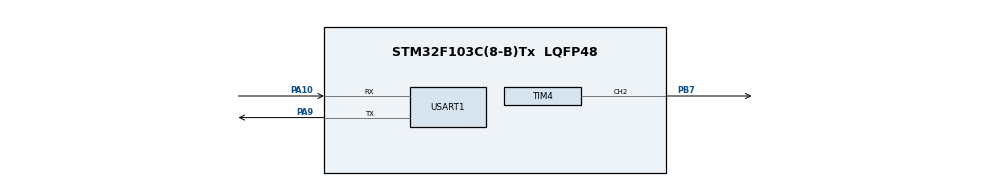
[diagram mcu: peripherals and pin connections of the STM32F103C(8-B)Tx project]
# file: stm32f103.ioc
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Dma.Request0=TIM4_CH2
Dma.Request1=USART1_RX
Dma.TIM4_CH2.0.Direction=DMA_MEMORY_TO_PERIPH
Dma.TIM4_CH2.0.Instance=DMA1_Channel4
Dma.TIM4_CH2.0.MemDataAlignment=DMA_MDATAALIGN_BYTE
Dma.TIM4_CH2.0.MemInc=DMA_MINC_ENABLE
Dma.TIM4_CH2.0.Mode=DMA_NORMAL
Dma.TIM4_CH2.0.PeriphDataAlignment=DMA_PDATAALIGN_HALFWORD
Dma.TIM4_CH2.0.PeriphInc=DMA_PINC_DISABLE
Dma.TIM4_CH2.0.Priority=DMA_PRIORITY_HIGH
Dma.USART1_RX.1.Direction=DMA_PERIPH_TO_MEMORY
Dma.USART1_RX.1.Instance=DMA1_Channel5
Dma.USART1_RX.1.MemDataAlignment=DMA_MDATAALIGN_BYTE
Dma.USART1_RX.1.MemInc=DMA_MINC_ENABLE
Dma.USART1_RX.1.Mode=DMA_NORMAL
Dma.USART1_RX.1.PeriphDataAlignment=DMA_PDATAALIGN_BYTE
Dma.USART1_RX.1.PeriphInc=DMA_PINC_DISABLE
Dma.USART1_RX.1.Priority=DMA_PRIORITY_HIGH
FREERTOS.BinarySemaphores01=ledCtrlSem,Dynamic,NULL
FREERTOS.Tasks01=LedSchedule,0,128,startLedSchedule,Default,NULL,Dynamic,NULL,NULL
Mcu.Family=STM32F1
Mcu.Name=STM32F103C(8-B)Tx
Mcu.Package=LQFP48
NVIC.DMA1_Channel4_IRQn=true\:5\:0\:false\:false\:true\:true\:false
NVIC.DMA1_Channel5_IRQn=true\:5\:0\:false\:false\:true\:true\:false
NVIC.PriorityGroup=NVIC_PRIORITYGROUP_4
NVIC.USART1_IRQn=true\:5\:0\:false\:false\:true\:true\:true
PA10.Mode=Asynchronous
PA10.Signal=USART1_RX
PA13.Mode=Serial_Wire
PA13.Signal=SYS_JTMS-SWDIO
PA14.Mode=Serial_Wire
PA14.Signal=SYS_JTCK-SWCLK
PA9.Mode=Asynchronous
PA9.Signal=USART1_TX
PB7.Signal=S_TIM4_CH2
PD0-OSC_IN.Mode=HSE-External-Oscillator
PD0-OSC_IN.Signal=RCC_OSC_IN
PD1-OSC_OUT.Mode=HSE-External-Oscillator
PD1-OSC_OUT.Signal=RCC_OSC_OUT
ProjectManager.HeapSize=0x200
ProjectManager.StackSize=0x400
ProjectManager.TargetToolchain=SW4STM32
RCC.AHBFreq_Value=72000000
RCC.APB1CLKDivider=RCC_HCLK_DIV2
RCC.APB1Freq_Value=36000000
RCC.APB1TimFreq_Value=72000000
RCC.APB2Freq_Value=72000000
RCC.APB2TimFreq_Value=72000000
RCC.HCLKFreq_Value=72000000
RCC.PLLMUL=RCC_PLL_MUL9
RCC.PLLSourceVirtual=RCC_PLLSOURCE_HSE
RCC.SYSCLKFreq_VALUE=72000000
RCC.SYSCLKSource=RCC_SYSCLKSOURCE_PLLCLK
RCC.USBFreq_Value=72000000
SH.S_TIM4_CH2.0=TIM4_CH2,PWM Generation2 CH2
TIM4.Channel-PWM\ Generation2\ CH2=TIM_CHANNEL_2
TIM4.Period=90-1
USART1.VirtualMode=VM_ASYNC
VP_FREERTOS_VS_ENABLE.Mode=Enabled
board=custom

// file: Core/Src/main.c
/**
  ******************************************************************************
  * @file           : main.c
  * @brief          : Main program body
  ******************************************************************************
  * This notice applies to any and all portions of this file
  * that are not between comment pairs USER CODE BEGIN and
  * USER CODE END. Other portions of this file, whether
  * inserted by the user or by software development tools
  * are owned by their respective copyright owners.
  *
  * Copyright (c) 2018 STMicroelectronics International N.V.
  * All rights reserved.
  *
  * Redistribution and use in source and binary forms, with or without
  * modification, are permitted, provided that the following conditions are met:
  *
  * 1. Redistribution of source code must retain the above copyright notice,
  *    this list of conditions and the following disclaimer.
  * 2. Redistributions in binary form must reproduce the above copyright notice,
  *    this list of conditions and the following disclaimer in the documentation
  *    and/or other materials provided with the distribution.
  * 3. Neither the name of STMicroelectronics nor the names of other
  *    contributors to this software may be used to endorse or promote products
  *    derived from this software without specific written permission.
  * 4. This software, including modifications and/or derivative works of this
  *    software, must execute solely and exclusively on microcontroller or
  *    microprocessor devices manufactured by or for STMicroelectronics.
  * 5. Redistribution and use of this software other than as permitted under
  *    this license is void and will automatically terminate your rights under
  *    this license.
  *
  * THIS SOFTWARE IS PROVIDED BY STMICROELECTRONICS AND CONTRIBUTORS "AS IS"
  * AND ANY EXPRESS, IMPLIED OR STATUTORY WARRANTIES, INCLUDING, BUT NOT
  * LIMITED TO, THE IMPLIED WARRANTIES OF MERCHANTABILITY, FITNESS FOR A
  * PARTICULAR PURPOSE AND NON-INFRINGEMENT OF THIRD PARTY INTELLECTUAL PROPERTY
  * RIGHTS ARE DISCLAIMED TO THE FULLEST EXTENT PERMITTED BY LAW. IN NO EVENT
  * SHALL STMICROELECTRONICS OR CONTRIBUTORS BE LIABLE FOR ANY DIRECT, INDIRECT,
  * INCIDENTAL, SPECIAL, EXEMPLARY, OR CONSEQUENTIAL DAMAGES (INCLUDING, BUT NOT
  * LIMITED TO, PROCUREMENT OF SUBSTITUTE GOODS OR SERVICES; LOSS OF USE, DATA,
  * OR PROFITS; OR BUSINESS INTERRUPTION) HOWEVER CAUSED AND ON ANY THEORY OF
  * LIABILITY, WHETHER IN CONTRACT, STRICT LIABILITY, OR TORT (INCLUDING
  * NEGLIGENCE OR OTHERWISE) ARISING IN ANY WAY OUT OF THE USE OF THIS SOFTWARE,
  * EVEN IF ADVISED OF THE POSSIBILITY OF SUCH DAMAGE.
  *
  ******************************************************************************
  */
#include "main.h"
#include "cmsis_os.h"
#include "dma.h"
#include "tim.h"
#include "usart.h"
#include "gpio.h"

/* USER CODE BEGIN PV */
/* Private variables ---------------------------------------------------------*/

/* USER CODE END PV */

static void LL_Init(void);
void SystemClock_Config(void);
void MX_FREERTOS_Init(void);

/* USER CODE BEGIN PFP */
/* Private function prototypes -----------------------------------------------*/

/* USER CODE END PFP */

int main(void)
{

  /* MCU Configuration----------------------------------------------------------*/

  /* Reset of all peripherals, Initializes the Flash interface and the Systick. */
  LL_Init();

  /* Configure the system clock */
  SystemClock_Config();

  /* Initialize all configured peripherals */
  MX_GPIO_Init();
  MX_DMA_Init();
  MX_TIM4_Init();
  MX_USART1_UART_Init();

  /* Call init function for freertos objects (in freertos.c) */
  MX_FREERTOS_Init();

  /* Start scheduler */
  osKernelStart();

  /* We should never get here as control is now taken by the scheduler */

  /* Infinite loop */
  while (1)
  {

  }

}
static void LL_Init(void)
{

  LL_APB2_GRP1_EnableClock(LL_APB2_GRP1_PERIPH_AFIO);
  LL_APB1_GRP1_EnableClock(LL_APB1_GRP1_PERIPH_PWR);

  NVIC_SetPriorityGrouping(NVIC_PRIORITYGROUP_4);

  /* System interrupt init*/
  /* MemoryManagement_IRQn interrupt configuration */
  NVIC_SetPriority(MemoryManagement_IRQn, NVIC_EncodePriority(NVIC_GetPriorityGrouping(),0, 0));
  /* BusFault_IRQn interrupt configuration */
  NVIC_SetPriority(BusFault_IRQn, NVIC_EncodePriority(NVIC_GetPriorityGrouping(),0, 0));
  /* UsageFault_IRQn interrupt configuration */
  NVIC_SetPriority(UsageFault_IRQn, NVIC_EncodePriority(NVIC_GetPriorityGrouping(),0, 0));
  /* SVCall_IRQn interrupt configuration */
  NVIC_SetPriority(SVCall_IRQn, NVIC_EncodePriority(NVIC_GetPriorityGrouping(),0, 0));
  /* DebugMonitor_IRQn interrupt configuration */
  NVIC_SetPriority(DebugMonitor_IRQn, NVIC_EncodePriority(NVIC_GetPriorityGrouping(),0, 0));
  /* PendSV_IRQn interrupt configuration */
  NVIC_SetPriority(PendSV_IRQn, NVIC_EncodePriority(NVIC_GetPriorityGrouping(),15, 0));
  /* SysTick_IRQn interrupt configuration */
  NVIC_SetPriority(SysTick_IRQn, NVIC_EncodePriority(NVIC_GetPriorityGrouping(),15, 0));

    /**NOJTAG: JTAG-DP Disabled and SW-DP Enabled
    */
  LL_GPIO_AF_Remap_SWJ_NOJTAG();

}

void SystemClock_Config(void)
{

  LL_FLASH_SetLatency(LL_FLASH_LATENCY_2);

   if(LL_FLASH_GetLatency() != LL_FLASH_LATENCY_2)
  {
    Error_Handler();
  }
  LL_RCC_HSE_Enable();

   /* Wait till HSE is ready */
  while(LL_RCC_HSE_IsReady() != 1)
  {

  }
  LL_RCC_PLL_ConfigDomain_SYS(LL_RCC_PLLSOURCE_HSE_DIV_1, LL_RCC_PLL_MUL_9);

  LL_RCC_PLL_Enable();

   /* Wait till PLL is ready */
  while(LL_RCC_PLL_IsReady() != 1)
  {

  }
  LL_RCC_SetAHBPrescaler(LL_RCC_SYSCLK_DIV_1);

  LL_RCC_SetAPB1Prescaler(LL_RCC_APB1_DIV_2);

  LL_RCC_SetAPB2Prescaler(LL_RCC_APB2_DIV_1);

  LL_RCC_SetSysClkSource(LL_RCC_SYS_CLKSOURCE_PLL);

   /* Wait till System clock is ready */
  while(LL_RCC_GetSysClkSource() != LL_RCC_SYS_CLKSOURCE_STATUS_PLL)
  {

  }
  LL_Init1msTick(72000000);

  LL_SYSTICK_SetClkSource(LL_SYSTICK_CLKSOURCE_HCLK);

  LL_SetSystemCoreClock(72000000);

  /* SysTick_IRQn interrupt configuration */
  NVIC_SetPriority(SysTick_IRQn, NVIC_EncodePriority(NVIC_GetPriorityGrouping(),15, 0));
}

void _Error_Handler(char *file, int line)
{
  while(1)
  {
  }
}

/************************ (C) COPYRIGHT STMicroelectronics *****END OF FILE****/

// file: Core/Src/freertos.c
/* USER CODE BEGIN Header */
/**
 ******************************************************************************
 * File Name          : freertos.c
 * Description        : Code for freertos applications
 ******************************************************************************
 * This notice applies to any and all portions of this file
 * that are not between comment pairs USER CODE BEGIN and
 * USER CODE END. Other portions of this file, whether
 * inserted by the user or by software development tools
 * are owned by their respective copyright owners.
 *
 * Copyright (c) 2018 STMicroelectronics International N.V.
 * All rights reserved.
 *
 * Redistribution and use in source and binary forms, with or without
 * modification, are permitted, provided that the following conditions are met:
 *
 * 1. Redistribution of source code must retain the above copyright notice,
 *    this list of conditions and the following disclaimer.
 * 2. Redistributions in binary form must reproduce the above copyright notice,
 *    this list of conditions and the following disclaimer in the documentation
 *    and/or other materials provided with the distribution.
 * 3. Neither the name of STMicroelectronics nor the names of other
 *    contributors to this software may be used to endorse or promote products
 *    derived from this software without specific written permission.
 * 4. This software, including modifications and/or derivative works of this
 *    software, must execute solely and exclusively on microcontroller or
 *    microprocessor devices manufactured by or for STMicroelectronics.
 * 5. Redistribution and use of this software other than as permitted under
 *    this license is void and will automatically terminate your rights under
 *    this license.
 *
 * THIS SOFTWARE IS PROVIDED BY STMICROELECTRONICS AND CONTRIBUTORS "AS IS"
 * AND ANY EXPRESS, IMPLIED OR STATUTORY WARRANTIES, INCLUDING, BUT NOT
 * LIMITED TO, THE IMPLIED WARRANTIES OF MERCHANTABILITY, FITNESS FOR A
 * PARTICULAR PURPOSE AND NON-INFRINGEMENT OF THIRD PARTY INTELLECTUAL PROPERTY
 * RIGHTS ARE DISCLAIMED TO THE FULLEST EXTENT PERMITTED BY LAW. IN NO EVENT
 * SHALL STMICROELECTRONICS OR CONTRIBUTORS BE LIABLE FOR ANY DIRECT, INDIRECT,
 * INCIDENTAL, SPECIAL, EXEMPLARY, OR CONSEQUENTIAL DAMAGES (INCLUDING, BUT NOT
 * LIMITED TO, PROCUREMENT OF SUBSTITUTE GOODS OR SERVICES; LOSS OF USE, DATA,
 * OR PROFITS; OR BUSINESS INTERRUPTION) HOWEVER CAUSED AND ON ANY THEORY OF
 * LIABILITY, WHETHER IN CONTRACT, STRICT LIABILITY, OR TORT (INCLUDING
 * NEGLIGENCE OR OTHERWISE) ARISING IN ANY WAY OUT OF THE USE OF THIS SOFTWARE,
 * EVEN IF ADVISED OF THE POSSIBILITY OF SUCH DAMAGE.
 *
 ******************************************************************************
 */
/* USER CODE END Header */

#include "FreeRTOS.h"
#include "task.h"
#include "main.h"
#include "cmsis_os.h"

/* USER CODE BEGIN Includes */
#include "ws2812b.h"

/* USER CODE END Includes */

osThreadId LedScheduleHandle;
osSemaphoreId ledCtrlSemHandle;

void startLedSchedule(void const * argument);

void MX_FREERTOS_Init(void); /* (MISRA C 2004 rule 8.1) */

void MX_FREERTOS_Init(void) {

  /* Create the semaphores(s) */
  /* definition and creation of ledCtrlSem */
  osSemaphoreDef(ledCtrlSem);
  ledCtrlSemHandle = osSemaphoreCreate(osSemaphore(ledCtrlSem), 1);

  /* Create the thread(s) */
  /* definition and creation of LedSchedule */
  osThreadDef(LedSchedule, startLedSchedule, osPriorityNormal, 0, 128);
  LedScheduleHandle = osThreadCreate(osThread(LedSchedule), NULL);

}

void startLedSchedule(void const * argument)
{

  /* USER CODE BEGIN startLedSchedule */
	/* Infinite loop */
	run();
  /* USER CODE END startLedSchedule */
}

/************************ (C) COPYRIGHT STMicroelectronics *****END OF FILE****/
